VERSION "6.0"

NS_ :

BS_:

BU_:

BO_ 1568 Msg1: 2 Peripherals
 SG_ sig22 m2 : 15|8@0+ (1,0) [0|1] "" Vector__XXX
 SG_ sig12 m1 : 15|8@0+ (1,0) [0|1] "" Vector__XXX
 SG_ sig1 M : 7|8@0+ (1,0) [0|0] "" Vector__XXX

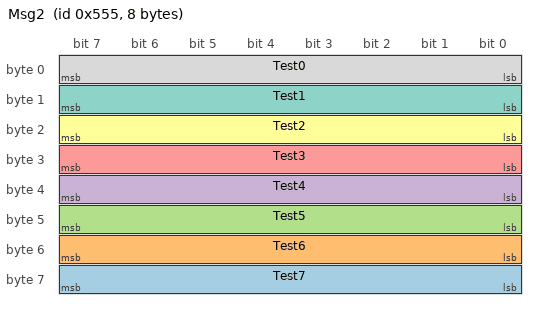
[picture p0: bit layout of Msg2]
BO_ 1365 Msg2: 8 ECU
 SG_ Test7 : 63|8@0+ (1,0) [0|0] "" Vector__XXX
 SG_ Test6 : 55|8@0+ (1,0) [0|0] "" Vector__XXX
 SG_ Test5 : 47|8@0+ (1,0) [0|0] "" Vector__XXX
 SG_ Test4 : 39|8@0+ (1,0) [0|0] "" Vector__XXX
 SG_ Test3 : 31|8@0+ (1,0) [0|0] "" Vector__XXX
 SG_ Test2 : 23|8@0+ (1,0) [0|0] "" Vector__XXX
 SG_ Test1 : 15|8@0+ (1,0) [0|0] "" Vector__XXX
 SG_ Test0 : 7|8@0+ (1,0) [0|0] "" Vector__XXX

BO_TX_BU_ 1365 : ECU,Peripherals;

CM_ SG_ 1568 sig22 "another comment for sig1=2";
CM_ SG_ 1568 sig12 "another comment for sig1=1";
CM_ SG_ 1568 sig1 "a comment";
CM_ BO_ 1365 "test";

VAL_ 1365 Test7 1 "A" 2 "B" 3 "C" 4 "D" ;
